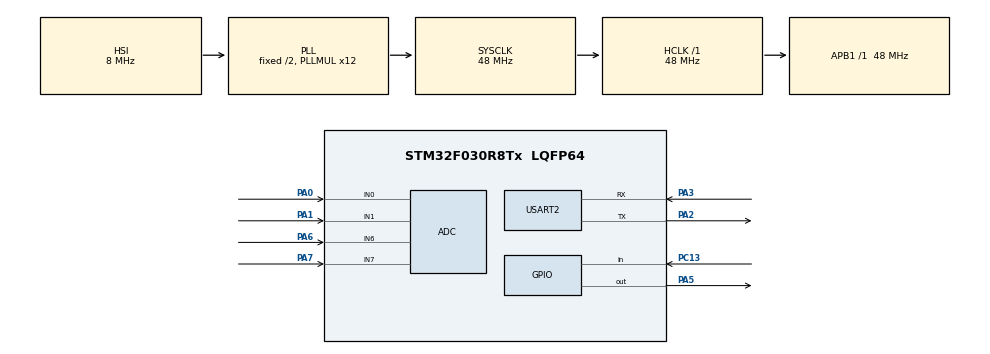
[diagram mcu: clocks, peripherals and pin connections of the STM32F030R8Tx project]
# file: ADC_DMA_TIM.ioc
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ADC.ClockPrescaler=ADC_CLOCK_SYNC_PCLK_DIV4
ADC.DMAContinuousRequests=ENABLE
ADC.EOCSelection=ADC_EOC_SEQ_CONV
ADC.ExternalTrigConv=ADC_EXTERNALTRIGCONV_T3_TRGO
ADC.SamplingTime=ADC_SAMPLETIME_28CYCLES_5
Dma.ADC.0.Direction=DMA_PERIPH_TO_MEMORY
Dma.ADC.0.Instance=DMA1_Channel1
Dma.ADC.0.MemDataAlignment=DMA_MDATAALIGN_WORD
Dma.ADC.0.MemInc=DMA_MINC_ENABLE
Dma.ADC.0.Mode=DMA_CIRCULAR
Dma.ADC.0.PeriphDataAlignment=DMA_PDATAALIGN_WORD
Dma.ADC.0.PeriphInc=DMA_PINC_DISABLE
Dma.ADC.0.Priority=DMA_PRIORITY_LOW
Dma.Request0=ADC
Mcu.Family=STM32F0
Mcu.Name=STM32F030R8Tx
Mcu.Package=LQFP64
NVIC.ADC1_IRQn=true\:0\:0\:false\:false\:true\:true\:true
NVIC.DMA1_Channel1_IRQn=true\:0\:0\:false\:false\:true\:false\:true
NVIC.TIM1_BRK_UP_TRG_COM_IRQn=true\:3\:0\:false\:false\:true\:false\:true
NVIC.TimeBase=TIM1_BRK_UP_TRG_COM_IRQn
NVIC.TimeBaseIP=TIM1
PA0.Mode=IN0
PA0.Signal=ADC_IN0
PA1.Mode=IN1
PA1.Signal=ADC_IN1
PA2.Mode=Asynchronous
PA2.Signal=USART2_TX
PA3.Mode=Asynchronous
PA3.Signal=USART2_RX
PA5.Signal=GPIO_Output
PA6.Mode=IN6
PA6.Signal=ADC_IN6
PA7.Mode=IN7
PA7.Signal=ADC_IN7
PC13.Signal=GPIO_Input
ProjectManager.HeapSize=0x200
ProjectManager.StackSize=0x400
ProjectManager.TargetToolchain=STM32CubeIDE
RCC.AHBFreq_Value=48000000
RCC.APB1Freq_Value=48000000
RCC.APB1TimFreq_Value=48000000
RCC.HCLKFreq_Value=48000000
RCC.PLLMUL=RCC_PLL_MUL12
RCC.SYSCLKFreq_VALUE=48000000
RCC.SYSCLKSource=RCC_SYSCLKSOURCE_PLLCLK
TIM3.Period=100
TIM3.Prescaler=4800
TIM3.TIM_MasterOutputTrigger=TIM_TRGO_UPDATE
USART2.VirtualMode-Asynchronous=VM_ASYNC
VP_SYS_VS_tim1.Mode=TIM1
VP_TIM3_VS_ClockSourceINT.Mode=Internal
board=NUCLEO-F030R8

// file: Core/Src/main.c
/* USER CODE BEGIN Header */
/**
  ******************************************************************************
  * @file           : main.c
  * @brief          : Main program body
  ******************************************************************************
  * @attention
  *
  * <h2><center>&copy; Copyright (c) 2021 STMicroelectronics.
  * All rights reserved.</center></h2>
  *
  * This software component is licensed by ST under BSD 3-Clause license,
  * the "License"; You may not use this file except in compliance with the
  * License. You may obtain a copy of the License at:
  *                        opensource.org/licenses/BSD-3-Clause
  *
  ******************************************************************************
  */
/* USER CODE END Header */
#include "main.h"

ADC_HandleTypeDef hadc;
DMA_HandleTypeDef hdma_adc;

TIM_HandleTypeDef htim3;

UART_HandleTypeDef huart2;

void SystemClock_Config(void);
static void MX_GPIO_Init(void);
static void MX_DMA_Init(void);
static void MX_ADC_Init(void);
static void MX_TIM3_Init(void);
static void MX_USART2_UART_Init(void);

/* USER CODE BEGIN 0 */
uint32_t adcVal[4];

int _write(int file, char *outgoing, int len) {
   HAL_UART_Transmit(&huart2, outgoing, len, 100);
   return len;
}

/* USER CODE END 0 */

int main(void)
{

  /* MCU Configuration--------------------------------------------------------*/

  /* Reset of all peripherals, Initializes the Flash interface and the Systick. */
  HAL_Init();

  /* Configure the system clock */
  SystemClock_Config();

  /* Initialize all configured peripherals */
  MX_GPIO_Init();
  MX_DMA_Init();
  MX_ADC_Init();
  MX_TIM3_Init();
  MX_USART2_UART_Init();
  /* USER CODE BEGIN 2 */
  //Start Timer
  HAL_TIM_Base_Start(&htim3);
  //Start ADC as DMA
  HAL_ADC_Start_DMA(&hadc, adcVal, 4);

  /* USER CODE END 2 */

  /* Infinite loop */
  while (1)
  {

  }
}

void SystemClock_Config(void)
{
  RCC_OscInitTypeDef RCC_OscInitStruct = {0};
  RCC_ClkInitTypeDef RCC_ClkInitStruct = {0};

  /** Initializes the RCC Oscillators according to the specified parameters
  * in the RCC_OscInitTypeDef structure.
  */
  RCC_OscInitStruct.OscillatorType = RCC_OSCILLATORTYPE_HSI;
  RCC_OscInitStruct.HSIState = RCC_HSI_ON;
  RCC_OscInitStruct.HSICalibrationValue = RCC_HSICALIBRATION_DEFAULT;
  RCC_OscInitStruct.PLL.PLLState = RCC_PLL_ON;
  RCC_OscInitStruct.PLL.PLLSource = RCC_PLLSOURCE_HSI;
  RCC_OscInitStruct.PLL.PLLMUL = RCC_PLL_MUL12;
  RCC_OscInitStruct.PLL.PREDIV = RCC_PREDIV_DIV1;
  if (HAL_RCC_OscConfig(&RCC_OscInitStruct) != HAL_OK)
  {
    Error_Handler();
  }
  /** Initializes the CPU, AHB and APB buses clocks
  */
  RCC_ClkInitStruct.ClockType = RCC_CLOCKTYPE_HCLK|RCC_CLOCKTYPE_SYSCLK
                              |RCC_CLOCKTYPE_PCLK1;
  RCC_ClkInitStruct.SYSCLKSource = RCC_SYSCLKSOURCE_PLLCLK;
  RCC_ClkInitStruct.AHBCLKDivider = RCC_SYSCLK_DIV1;
  RCC_ClkInitStruct.APB1CLKDivider = RCC_HCLK_DIV1;

  if (HAL_RCC_ClockConfig(&RCC_ClkInitStruct, FLASH_LATENCY_1) != HAL_OK)
  {
    Error_Handler();
  }
}

static void MX_ADC_Init(void)
{

  ADC_ChannelConfTypeDef sConfig = {0};

  /** Configure the global features of the ADC (Clock, Resolution, Data Alignment and number of conversion)
  */
  hadc.Instance = ADC1;
  hadc.Init.ClockPrescaler = ADC_CLOCK_SYNC_PCLK_DIV4;
  hadc.Init.Resolution = ADC_RESOLUTION_12B;
  hadc.Init.DataAlign = ADC_DATAALIGN_RIGHT;
  hadc.Init.ScanConvMode = ADC_SCAN_DIRECTION_FORWARD;
  hadc.Init.EOCSelection = ADC_EOC_SEQ_CONV;
  hadc.Init.LowPowerAutoWait = DISABLE;
  hadc.Init.LowPowerAutoPowerOff = DISABLE;
  hadc.Init.ContinuousConvMode = DISABLE;
  hadc.Init.DiscontinuousConvMode = DISABLE;
  hadc.Init.ExternalTrigConv = ADC_EXTERNALTRIGCONV_T3_TRGO;
  hadc.Init.ExternalTrigConvEdge = ADC_EXTERNALTRIGCONVEDGE_RISING;
  hadc.Init.DMAContinuousRequests = ENABLE;
  hadc.Init.Overrun = ADC_OVR_DATA_PRESERVED;
  if (HAL_ADC_Init(&hadc) != HAL_OK)
  {
    Error_Handler();
  }
  /** Configure for the selected ADC regular channel to be converted.
  */
  sConfig.Channel = ADC_CHANNEL_0;
  sConfig.Rank = ADC_RANK_CHANNEL_NUMBER;
  sConfig.SamplingTime = ADC_SAMPLETIME_28CYCLES_5;
  if (HAL_ADC_ConfigChannel(&hadc, &sConfig) != HAL_OK)
  {
    Error_Handler();
  }
  /** Configure for the selected ADC regular channel to be converted.
  */
  sConfig.Channel = ADC_CHANNEL_1;
  if (HAL_ADC_ConfigChannel(&hadc, &sConfig) != HAL_OK)
  {
    Error_Handler();
  }
  /** Configure for the selected ADC regular channel to be converted.
  */
  sConfig.Channel = ADC_CHANNEL_6;
  if (HAL_ADC_ConfigChannel(&hadc, &sConfig) != HAL_OK)
  {
    Error_Handler();
  }
  /** Configure for the selected ADC regular channel to be converted.
  */
  sConfig.Channel = ADC_CHANNEL_7;
  if (HAL_ADC_ConfigChannel(&hadc, &sConfig) != HAL_OK)
  {
    Error_Handler();
  }

}

static void MX_TIM3_Init(void)
{

  TIM_ClockConfigTypeDef sClockSourceConfig = {0};
  TIM_MasterConfigTypeDef sMasterConfig = {0};

  htim3.Instance = TIM3;
  htim3.Init.Prescaler = 4800;
  htim3.Init.CounterMode = TIM_COUNTERMODE_UP;
  htim3.Init.Period = 1000;
  htim3.Init.ClockDivision = TIM_CLOCKDIVISION_DIV1;
  htim3.Init.AutoReloadPreload = TIM_AUTORELOAD_PRELOAD_DISABLE;
  if (HAL_TIM_Base_Init(&htim3) != HAL_OK)
  {
    Error_Handler();
  }
  sClockSourceConfig.ClockSource = TIM_CLOCKSOURCE_INTERNAL;
  if (HAL_TIM_ConfigClockSource(&htim3, &sClockSourceConfig) != HAL_OK)
  {
    Error_Handler();
  }
  sMasterConfig.MasterOutputTrigger = TIM_TRGO_UPDATE;
  sMasterConfig.MasterSlaveMode = TIM_MASTERSLAVEMODE_DISABLE;
  if (HAL_TIMEx_MasterConfigSynchronization(&htim3, &sMasterConfig) != HAL_OK)
  {
    Error_Handler();
  }

}

static void MX_USART2_UART_Init(void)
{

  huart2.Instance = USART2;
  huart2.Init.BaudRate = 38400;
  huart2.Init.WordLength = UART_WORDLENGTH_8B;
  huart2.Init.StopBits = UART_STOPBITS_1;
  huart2.Init.Parity = UART_PARITY_NONE;
  huart2.Init.Mode = UART_MODE_TX_RX;
  huart2.Init.HwFlowCtl = UART_HWCONTROL_NONE;
  huart2.Init.OverSampling = UART_OVERSAMPLING_16;
  huart2.Init.OneBitSampling = UART_ONE_BIT_SAMPLE_DISABLE;
  huart2.AdvancedInit.AdvFeatureInit = UART_ADVFEATURE_NO_INIT;
  if (HAL_UART_Init(&huart2) != HAL_OK)
  {
    Error_Handler();
  }

}

static void MX_DMA_Init(void)
{

  /* DMA controller clock enable */
  __HAL_RCC_DMA1_CLK_ENABLE();

  /* DMA interrupt init */
  /* DMA1_Channel1_IRQn interrupt configuration */
  HAL_NVIC_SetPriority(DMA1_Channel1_IRQn, 0, 0);
  HAL_NVIC_EnableIRQ(DMA1_Channel1_IRQn);

}

static void MX_GPIO_Init(void)
{
  GPIO_InitTypeDef GPIO_InitStruct = {0};

  /* GPIO Ports Clock Enable */
  __HAL_RCC_GPIOC_CLK_ENABLE();
  __HAL_RCC_GPIOA_CLK_ENABLE();

  /*Configure GPIO pin Output Level */
  HAL_GPIO_WritePin(GPIOA, GPIO_PIN_5, GPIO_PIN_RESET);

  /*Configure GPIO pin : PC13 */
  GPIO_InitStruct.Pin = GPIO_PIN_13;
  GPIO_InitStruct.Mode = GPIO_MODE_INPUT;
  GPIO_InitStruct.Pull = GPIO_NOPULL;
  HAL_GPIO_Init(GPIOC, &GPIO_InitStruct);

  /*Configure GPIO pin : PA5 */
  GPIO_InitStruct.Pin = GPIO_PIN_5;
  GPIO_InitStruct.Mode = GPIO_MODE_OUTPUT_PP;
  GPIO_InitStruct.Pull = GPIO_NOPULL;
  GPIO_InitStruct.Speed = GPIO_SPEED_FREQ_LOW;
  HAL_GPIO_Init(GPIOA, &GPIO_InitStruct);

}

/* USER CODE BEGIN 4 */
void HAL_ADC_ConvCpltCallback(ADC_HandleTypeDef* hadc)
{
  /* Prevent unused argument(s) compilation warning */
  UNUSED(hadc);

  /* NOTE : This function should not be modified. When the callback is needed,
            function HAL_ADC_ConvCpltCallback must be implemented in the user file.
   */

  HAL_GPIO_TogglePin(GPIOA, GPIO_PIN_5);
  printf("adcVal[0] %lu\n", adcVal[0]);
  printf("adcVal[1] %lu\n", adcVal[1]);
  printf("adcVal[2] %lu\n", adcVal[2]);
  printf("adcVal[3] %lu\n", adcVal[3]);
  printf("\n");
}
/* USER CODE END 4 */

void HAL_TIM_PeriodElapsedCallback(TIM_HandleTypeDef *htim)
{
  if (htim->Instance == TIM1) {
    HAL_IncTick();
  }
}

void Error_Handler(void)
{
  __disable_irq();
  while (1)
  {
  }
}

/************************ (C) COPYRIGHT STMicroelectronics *****END OF FILE****/
